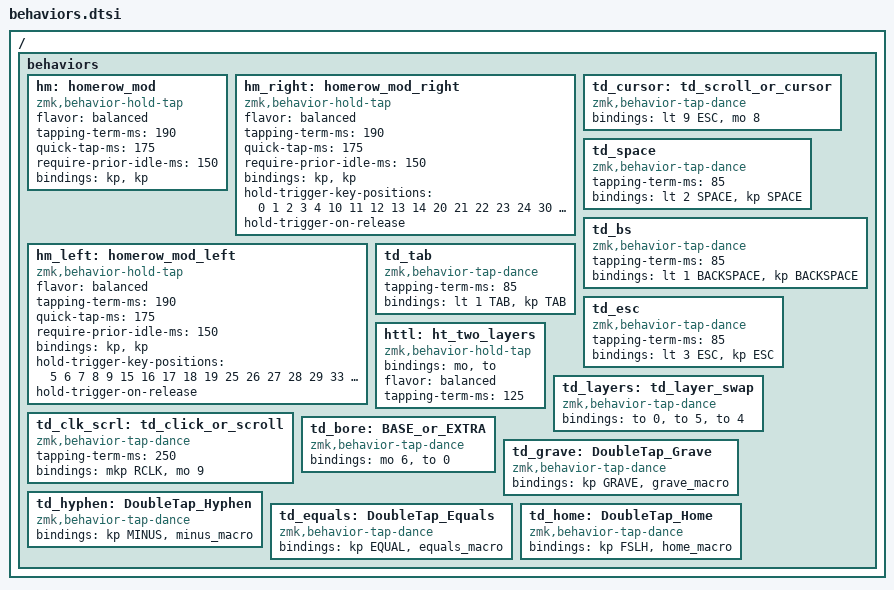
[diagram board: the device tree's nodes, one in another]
/ {
    behaviors {
        hm: homerow_mod {
            compatible = "zmk,behavior-hold-tap";
            #binding-cells = <2>;
            flavor = "balanced";
            tapping-term-ms = <190>; // triggers the hold behavior when the tapping-term-ms has expired
            quick-tap-ms = <175>; // If you press a tapped hold-tap again within quick-tap-ms milliseconds of the first press, it will always trigger the tap behavior.
            require-prior-idle-ms = <150>; // like quick-tap-ms however it will apply for any non-modifier key pressed before it
            bindings = <&kp>, <&kp>;  // hold, tap
        };

        hm_right: homerow_mod_right {
            compatible = "zmk,behavior-hold-tap";
            #binding-cells = <2>;
            flavor = "balanced";
            tapping-term-ms = <190>;
            quick-tap-ms = <175>;
            require-prior-idle-ms = <150>;
            bindings = <&kp>, <&kp>;
            hold-trigger-key-positions = <0 1 2 3 4 10 11 12 13 14 20 21 22 23 24 30 31 32>;
            hold-trigger-on-release;
        };

        hm_left: homerow_mod_left {
            compatible = "zmk,behavior-hold-tap";
            #binding-cells = <2>;
            flavor = "balanced";
            tapping-term-ms = <190>;
            quick-tap-ms = <175>;
            require-prior-idle-ms = <150>;
            bindings = <&kp>, <&kp>;
            hold-trigger-key-positions = <5 6 7 8 9 15 16 17 18 19 25 26 27 28 29 33 34 35>;
            hold-trigger-on-release;
        };

        td_cursor: td_scroll_or_cursor {
            compatible = "zmk,behavior-tap-dance";
            #binding-cells = <0>;
            bindings = <&lt 9 ESC>, <&mo 8>; // hold, tap, double_tap
        };

        td_space: td_space {
            compatible = "zmk,behavior-tap-dance";
            #binding-cells = <0>;
            tapping-term-ms = <85>;
            bindings = <&lt 2 SPACE>, <&kp SPACE>; // hold, tap, double_tap
        };

        td_bs: td_bs {
            compatible = "zmk,behavior-tap-dance";
            #binding-cells = <0>;
            tapping-term-ms = <85>;
            bindings = <&lt 1 BACKSPACE>, <&kp BACKSPACE>; // hold, tap, double_tap
        };

        td_tab: td_tab {
            compatible = "zmk,behavior-tap-dance";
            #binding-cells = <0>;
            tapping-term-ms = <85>;
            bindings = <&lt 1 TAB>, <&kp TAB>; // hold, tap, double_tap
        };

        td_esc: td_esc {
            compatible = "zmk,behavior-tap-dance";
            #binding-cells = <0>;
            tapping-term-ms = <85>;
            bindings = <&lt 3 ESC>, <&kp ESC>; // hold, tap, double_tap
        };

        httl: ht_two_layers {
            compatible = "zmk,behavior-hold-tap";
            bindings = <&mo>, <&to>;
            #binding-cells = <2>;
            flavor = "balanced";
            tapping-term-ms = <125>;
        };

        td_layers: td_layer_swap {
            compatible = "zmk,behavior-tap-dance";
            #binding-cells = <0>;
            bindings = <&to 0>, <&to 5>, <&to 4>; // tap, double_tap, tripple_tap
        };

        td_clk_scrl: td_click_or_scroll {
            compatible = "zmk,behavior-tap-dance";
            #binding-cells = <0>;
            tapping-term-ms = <250>;
            bindings = <&mkp RCLK>, <&mo 9>;  // tap/hold, double_tap
        };

        td_bore: BASE_or_EXTRA {
            compatible = "zmk,behavior-tap-dance";
            #binding-cells = <0>;
            bindings = <&mo 6>, <&to 0>;
        };

        td_grave: DoubleTap_Grave {
            compatible = "zmk,behavior-tap-dance";
            #binding-cells = <0>;
            bindings = <&kp GRAVE>, <&grave_macro>;
        };

        td_hyphen: DoubleTap_Hyphen {
            compatible = "zmk,behavior-tap-dance";
            #binding-cells = <0>;
            bindings = <&kp MINUS>, <&minus_macro>;
        };

        td_equals: DoubleTap_Equals {
            compatible = "zmk,behavior-tap-dance";
            #binding-cells = <0>;
            bindings = <&kp EQUAL>, <&equals_macro>;
        };

        td_home: DoubleTap_Home {
            compatible = "zmk,behavior-tap-dance";
            #binding-cells = <0>;
            bindings = <&kp FSLH>, <&home_macro>;
        };
    };
};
